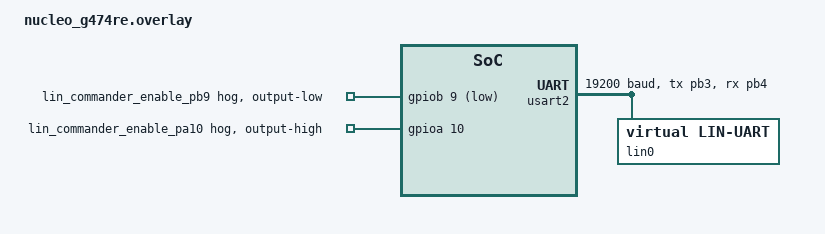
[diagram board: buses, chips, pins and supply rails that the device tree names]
&usart2 {
	pinctrl-0 = <&usart2_tx_pb3 &usart2_rx_pb4>;
	pinctrl-names = "default";
	current-speed = <115200>;
	status = "okay";
};

&gpiob {
	lin_commander_enable_pb9: lin_commander_enable_pb9 {
		gpio-hog;
		gpios = <9 GPIO_ACTIVE_LOW>;
		output-low;
	};
};

lin_uart: &usart2 {
    pinctrl-0 = <&usart2_tx_pb3 &usart2_rx_pb4>;
    pinctrl-names = "default";
    current-speed = <19200>;
    status = "okay";

	lin0 {
		compatible = "virtual,lin-uart";
		status = "okay";
		bitrate = <19200>;
		max-wait-percent = <150>;

		abstract_lin0: abstract_lin {
			compatible = "virtual,abstract-lin";
			type = "LIN_MODE_RESPONDER";

			lin2can0: lin2can {
				compatible = "virtual,lin2can";
			};
		};
	};
};

&gpioa {
	lin_commander_enable_pa10: lin_commander_enable_pa10 {
		gpio-hog;
		gpios = <10 GPIO_ACTIVE_HIGH>;
		output-high;
	};
};
